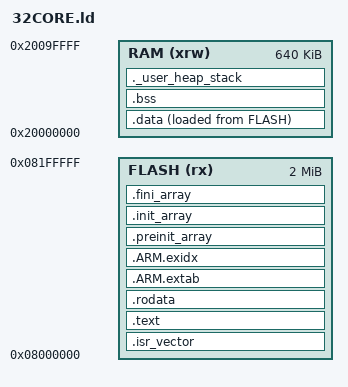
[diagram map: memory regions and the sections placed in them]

/* Entry point */
ENTRY(Reset_Handler)

/* Memory layout for STM32H562VGT6
 *
 * FLASH: 2 MiB
 * SRAM1: 256 KiB  @ 0x20000000
 * SRAM2:  64 KiB  @ 0x20040000
 * SRAM3: 320 KiB  @ 0x20050000
 *
 * SRAM1 + SRAM2 + SRAM3 are contiguous:
 * 0x20000000 .. 0x200A0000
 *
 * BKPSRAM is separate and is not included here.
 */

_Min_Heap_Size  = 0x200;
_Min_Stack_Size = 0x400;

MEMORY
{
    RAM   (xrw) : ORIGIN = 0x20000000, LENGTH = 640K
    FLASH (rx)  : ORIGIN = 0x08000000, LENGTH = 2048K
}

/* Stack starts at the end of RAM */
_estack = ORIGIN(RAM) + LENGTH(RAM);
_sstack = _estack - _Min_Stack_Size;

/* Sections */
SECTIONS
{
    /* Interrupt vector table */
    .isr_vector :
    {
        . = ALIGN(4);
        KEEP(*(.isr_vector))
        . = ALIGN(4);
    } > FLASH

    /* Program code */
    .text :
    {
        . = ALIGN(4);

        *(.text)
        *(.text*)
        *(.glue_7)
        *(.glue_7t)
        *(.eh_frame)

        KEEP(*(.init))
        KEEP(*(.fini))

        . = ALIGN(4);
        _etext = .;
    } > FLASH

    /* Read-only data */
    .rodata :
    {
        . = ALIGN(4);
        *(.rodata)
        *(.rodata*)
        . = ALIGN(4);
    } > FLASH

    /* ARM exception unwind tables */
    .ARM.extab :
    {
        . = ALIGN(4);
        *(.ARM.extab* .gnu.linkonce.armextab.*)
        . = ALIGN(4);
    } > FLASH

    .ARM.exidx :
    {
        . = ALIGN(4);
        __exidx_start = .;
        *(.ARM.exidx*)
        __exidx_end = .;
        . = ALIGN(4);
    } > FLASH

    /* Pre-initialization array */
    .preinit_array :
    {
        . = ALIGN(4);
        PROVIDE_HIDDEN(__preinit_array_start = .);
        KEEP(*(.preinit_array*))
        PROVIDE_HIDDEN(__preinit_array_end = .);
        . = ALIGN(4);
    } > FLASH

    /* C++ constructors */
    .init_array :
    {
        . = ALIGN(4);
        PROVIDE_HIDDEN(__init_array_start = .);
        KEEP(*(SORT(.init_array.*)))
        KEEP(*(.init_array))
        PROVIDE_HIDDEN(__init_array_end = .);
        . = ALIGN(4);
    } > FLASH

    /* C++ destructors */
    .fini_array :
    {
        . = ALIGN(4);
        PROVIDE_HIDDEN(__fini_array_start = .);
        KEEP(*(SORT(.fini_array.*)))
        KEEP(*(.fini_array))
        PROVIDE_HIDDEN(__fini_array_end = .);
        . = ALIGN(4);
    } > FLASH

    /* Initialized data: load from FLASH, execute from RAM */
    _sidata = LOADADDR(.data);

    .data :
    {
        . = ALIGN(4);
        _sdata = .;

        *(.data)
        *(.data*)
        *(.RamFunc)
        *(.RamFunc*)

        . = ALIGN(4);
        _edata = .;
    } > RAM AT > FLASH

    /* Zero-initialized data */
    .bss :
    {
        . = ALIGN(4);
        _sbss = .;
        __bss_start__ = _sbss;

        *(.bss)
        *(.bss*)
        *(COMMON)

        . = ALIGN(4);
        _ebss = .;
        __bss_end__ = _ebss;
    } > RAM

    /* Heap and minimum stack reservation */
    ._user_heap_stack :
    {
        . = ALIGN(8);
        PROVIDE(end = .);
        PROVIDE(_end = .);

        . = . + _Min_Heap_Size;
        . = . + _Min_Stack_Size;

        . = ALIGN(8);
    } > RAM

    /* Discard unused library metadata */
    /DISCARD/ :
    {
        libc.a (*)
        libm.a (*)
        libgcc.a (*)
    }

    /* ELF attributes */
    .ARM.attributes 0 :
    {
        *(.ARM.attributes)
    }
}

/* Fail the link if the minimum heap/stack reservation does not fit. */
ASSERT(
    (_end <= (ORIGIN(RAM) + LENGTH(RAM))),
    "Error: RAM overflow - data, heap and stack exceed RAM"
)

ASSERT(
    (_etext <= (ORIGIN(FLASH) + LENGTH(FLASH))),
    "Error: FLASH overflow"
)
